AUTOSAR XML (schema 4-0-3)
package /ComponentTypes
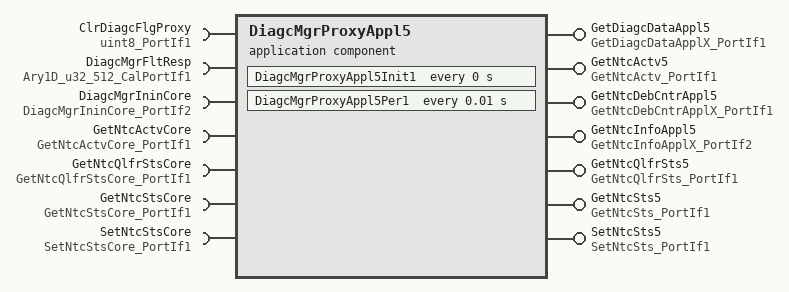
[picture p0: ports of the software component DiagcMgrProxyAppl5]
  application sw component type DiagcMgrProxyAppl5
    7 x provide port, all with server-com-spec{operation=Oper, queue-length=1}:
      GetDiagcDataAppl5: provided-interface=GetDiagcDataApplX_PortIf1
      GetNtcActv5: provided-interface=GetNtcActv_PortIf1
      GetNtcDebCntrAppl5: provided-interface=GetNtcDebCntrApplX_PortIf1
      GetNtcInfoAppl5: provided-interface=GetNtcInfoApplX_PortIf2
      GetNtcQlfrSts5: provided-interface=GetNtcQlfrSts_PortIf1
      GetNtcSts5: provided-interface=GetNtcSts_PortIf1
      SetNtcSts5: provided-interface=SetNtcSts_PortIf1
    7 x require port:
      ClrDiagcFlgProxy: nonqueued-receiver-com-spec{data-element=Val, filter=data-filter-type=ALWAYS, init-value=0}, required-interface=uint8_PortIf1
      DiagcMgrFltResp: parameter-require-com-spec{init-value=[0, 2147487488, 2147487488, 2147487488, 2147487488, 2147487488, 2147487488, 2147487488, 2147487488, 2147487488, 2147487488, 2147487488, 2147487488, 2147487488, 2147487488, 2147487488, 2147487488, 2147487488, 2147487488, 2147487488, 2147487488, 2147487488, 2147487488, 2147487488, 2147487488, 2147487488, 2147487488, 2147487488, 2147487488, 2147487488, 2147487488, 2147487488, 2147487488, 2147487488, 2147487488, 2147487488, 2147487488, 2147487488, 2147487488, 2147487488, 2147487488, 2147487488, 2147487488, 2147487488, 2147487488, 2147487488, 2147487488, 2147487488, 2147487488, 2147487488, 2147487488, 2147487488, 2147487488, 2147487488, 2147487488, 2147487488, 2147487488, 2147487488, 2147487488, 2147487488, 2147487488, 2147487488, 2147487488, 2147487488, 2147487488, 2147487488, 2147487488, 2147487488, 2147487488, 2147487488, 2147487488, 2147487488, 2147487488, 2147487488, 2147487488, 2147487488, 2147487488, 2147487488, 2147487488, 2147487488, 2147487488, 2147487488, 2147487488, 2147487488, 2147487488, 2147487488, 2147487488, 2147487488, 2147487488, 2147487488, 2147487488, 2147487488, 2147487488, 2147487488, 2147487488, 2147487488, 2147487488, 2147487488, 2147487488, 2147487488, 2147487488, 2147487488, 2147487488, 2147487488, 2147487488, 2147487488, 2147487488, 2147487488, 2147487488, 2147487488, 2147487488, 2147487488, 2147487488, 2147487488, 2147487488, 2147487488, 2147487488, 2147487488, 2147487488, 2147487488, 2147487488, 2147487488, 2147487488, 2147487488, 2147487488, 2147487488, 2147487488, 2147487488, 2147487488, 2147487488, 2147487488, 2147487488, 2147487488, 2147487488, 2147487488, 2147487488, 2147487488, 2147487488, 2147487488, 2147487488, 2147487488, 2147487488, 2147487488, 2147487488, 2147487488, 2147487488, 2147487488, 2147487488, 2147487488, 2147487488, 2147487488, 2147487488, 2147487488, 2147487488, 2147487488, 2147487488, 2147487488, 2147487488, 2147487488, 2147487488, 2147487488, 2147487488, 2147487488, 2147487488, 2147487488, 2147487488, 2147487488, 2147487488, 2147487488, 2147487488, 2147487488, 2147487488, 2147487488, 2147487488, 2147487488, 2147487488, 2147487488, 2147487488, 2147487488, 2147487488, 2147487488, 2147487488, 2147487488, 2147487488, 2147487488, 2147487488, 2147487488, 2147487488, 2147487488, 2147487488, 2147487488, 2147487488, 2147487488, 2147487488, 2147487488, 2147487488, 2147487488, 2147487488, 2147487488, 2147487488, 2147487488, 2147487488, 2147487488, 2147487488, 2147487488, 2147487488, 2147487488, 2147487488, 2147487488, 2147487488, 2147487488, 2147487488, 2147487488, 2147487488, 2147487488, 2147487488, 2147487488, 2147487488, 2147487488, 2147487488, 2147487488, 2147487488, 2147487488, 2147487488, 2147487488, 2147487488, 2147487488, 2147487488, 2147487488, 2147487488, 2147487488, 2147487488, 2147487488, 2147487488, 2147487488, 2147487488, 2147487488, 2147487488, 2147487488, 2147487488, 2147487488, 2147487488, 2147487488, 2147487488, 2147487488, 2147487488, 2147487488, 2147487488, 2147487488, 2147487488, 2147487488, 2147487488, 2147487488, 2147487488, 2147487488, 2147487488, 2147487488, 2147487488, 2147487488, 2147487488, 2147487488, 2147487488, 2147487488, 2147487488, 2147487488, 2147487488, 2147487488, 2147487488, 2147487488, 2147487488, 2147487488, 2147487488, 2147487488, 2147487488, 2147487488, 2147487488, 2147487488, 2147487488, 2147487488, 2147487488, 2147487488, 2147487488, 2147487488, 2147487488, 2147487488, 2147487488, 2147487488, 2147487488, 2147487488, 2147487488, 2147487488, 2147487488, 2147487488, 2147487488, 2147487488, 2147487488, 2147487488, 2147487488, 2147487488, 2147487488, 2147487488, 2147487488, 2147487488, 2147487488, 2147487488, 2147487488, 2147487488, 2147487488, 2147487488, 2147487488, 2147487488, 2147487488, 2147487488, 2147487488, 2147487488, 2147487488, 2147487488, 2147487488, 2147487488, 2147487488, 2147487488, 2147487488, 2147487488, 2147487488, 2147487488, 2147487488, 2147487488, 2147487488, 2147487488, 2147487488, 2147487488, 2147487488, 2147487488, 2147487488, 2147487488, 2147487488, 2147487488, 2147487488, 2147487488, 2147487488, 2147487488, 2147487488, 2147487488, 2147487488, 2147487488, 2147487488, 2147487488, 2147487488, 2147487488, 2147487488, 2147487488, 2147487488, 2147487488, 2147487488, 2147487488, 2147487488, 2147487488, 2147487488, 2147487488, 2147487488, 2147487488, 2147487488, 2147487488, 2147487488, 2147487488, 2147487488, 2147487488, 2147487488, 2147487488, 2147487488, 2147487488, 2147487488, 2147487488, 2147487488, 2147487488, 2147487488, 2147487488, 2147487488, 2147487488, 2147487488, 2147487488, 2147487488, 2147487488, 2147487488, 2147487488, 2147487488, 2147487488, 2147487488, 2147487488, 2147487488, 2147487488, 2147487488, 2147487488, 2147487488, 2147487488, 2147487488, 2147487488, 2147487488, 2147487488, 2147487488, 2147487488, 2147487488, 2147487488, 2147487488, 2147487488, 2147487488, 2147487488, 2147487488, 2147487488, 2147487488, 2147487488, 2147487488, 2147487488, 2147487488, 2147487488, 2147487488, 2147487488, 2147487488, 2147487488, 2147487488, 2147487488, 2147487488, 2147487488, 2147487488, 2147487488, 2147487488, 2147487488, 2147487488, 2147487488, 2147487488, 2147487488, 2147487488, 2147487488, 2147487488, 2147487488, 2147487488, 2147487488, 2147487488, 2147487488, 2147487488, 2147487488, 2147487488, 2147487488, 2147487488, 2147487488, 2147487488, 2147487488, 2147487488, 2147487488, 2147487488, 2147487488, 2147487488, 2147487488, 2147487488, 2147487488, 2147487488, 2147487488, 2147487488, 2147487488, 2147487488, 2147487488, 2147487488, 2147487488, 2147487488, 2147487488, 2147487488, 2147487488, 2147487488, 2147487488, 2147487488, 2147487488, 2147487488, 2147487488, 2147487488, 2147487488, 2147487488, 2147487488, 2147487488, 2147487488, 2147487488, 2147487488, 2147487488, 2147487488, 2147487488, 2147487488, 2147487488, 2147487488, 2147487488, 2147487488, 2147487488, 2147487488, 2147487488, 2147487488, 2147487488, 2147487488, 2147487488, 2147487488, 2147487488, 2147487488, 2147487488, 2147487488, 2147487488, 2147487488, 2147487488, 2147487488, 2147487488, 2147487488, 2147487488, 2147487488, 2147487488, 2147487488, 2147487488], parameter=Ary1D}, required-interface=Ary1D_u32_512_CalPortIf1
      DiagcMgrIninCore: required-interface=DiagcMgrIninCore_PortIf2
      GetNtcActvCore: required-interface=GetNtcActvCore_PortIf1
      GetNtcQlfrStsCore: required-interface=GetNtcQlfrStsCore_PortIf1
      GetNtcStsCore: required-interface=GetNtcStsCore_PortIf1
      SetNtcStsCore: required-interface=SetNtcStsCore_PortIf1
    behavior DiagcMgrProxyAppl5_InternalBehavior
      exclusive area DiagcMgrProxyAppl5
      ar-typed-per-instance-memorys:
        5 x data:
          DiagcData5: sw-calibration-access=READ-ONLY, type=DiagcDataRec1
          DiagcMgrNtcInfo5Ary: type=Ary1D_NtcInfoRec4_DiagcMgrProxyAppl5
          DiagcMgrNtcInfo5DebCntrAry: type=Ary1D_s16_DiagcMgrProxyAppl5
          PrevClrNtcFlg5: sw-calibration-access=READ-ONLY, type=uint8
          ProxySetNtcData5: sw-calibration-access=READ-ONLY, type=DiagcDataRec1
      timing event DiagcMgrProxyAppl5_InitEvent: start-on-event=DiagcMgrProxyAppl5Init1, period=0
      timing event TMT_DiagcMgrProxyAppl5Per1: start-on-event=DiagcMgrProxyAppl5Per1, period=0.01
      7 x operation invoked event:
        OIT_GetDiagcDataAppl5_Oper_GetDiagcDataAppl5_Oper: start-on-event=GetDiagcDataAppl5_Oper, operation=GetDiagcDataAppl5.Oper
        OIT_GetNtcActv5_Oper_GetNtcActv5_Oper: start-on-event=GetNtcActv5_Oper, operation=GetNtcActv5.Oper
        OIT_GetNtcDebCntrAppl5_Oper_GetNtcDebCntrAppl5_Oper: start-on-event=GetNtcDebCntrAppl5_Oper, operation=GetNtcDebCntrAppl5.Oper
        OIT_GetNtcInfoAppl5_Oper_GetNtcInfoAppl5_Oper: start-on-event=GetNtcInfoAppl5_Oper, operation=GetNtcInfoAppl5.Oper
        OIT_GetNtcQlfrSts5_Oper_GetNtcQlfrSts5_Oper: start-on-event=GetNtcQlfrSts5_Oper, operation=GetNtcQlfrSts5.Oper
        OIT_GetNtcSts5_Oper_GetNtcSts5_Oper: start-on-event=GetNtcSts5_Oper, operation=GetNtcSts5.Oper
        OIT_SetNtcSts5_Oper_SetNtcSts5_Oper: start-on-event=SetNtcSts5_Oper, operation=SetNtcSts5.Oper
      9 x runnable:
        DiagcMgrProxyAppl5Init1
          sync call SC_DiagcMgrIninCore_Oper: operation=DiagcMgrIninCore.Oper, timeout=0
        DiagcMgrProxyAppl5Per1: can-enter-exclusive-area=DiagcMgrProxyAppl5
          data-receive-point-by-arguments:
            access REC_ClrNtcFlg_Val: accessed-variable=ClrDiagcFlgProxy.Val
        GetDiagcDataAppl5_Oper
        GetNtcActv5_Oper: can-be-invoked-concurrently=true
          sync call SC_GetNtcActvCore_Oper: operation=GetNtcActvCore.Oper, timeout=0
        GetNtcDebCntrAppl5_Oper
        GetNtcInfoAppl5_Oper
        GetNtcQlfrSts5_Oper: can-be-invoked-concurrently=true
          sync call SC_GetNtcQlfrStsCore_Oper: operation=GetNtcQlfrStsCore.Oper, timeout=0
        GetNtcSts5_Oper: can-be-invoked-concurrently=true
          sync call SC_GetNtcStsCore_Oper: operation=GetNtcStsCore.Oper, timeout=0
        SetNtcSts5_Oper: can-be-invoked-concurrently=true
          sync call SC_SetNtcStsCore_Oper: operation=SetNtcStsCore.Oper, timeout=0
  swc implementation DiagcMgrProxyAppl5_Implementation: behavior=DiagcMgrProxyAppl5_InternalBehavior
    code-descriptors:
      code Default: artifact-descriptors=autosar-engineering-object={short-label=Default, category=SWSRC}
